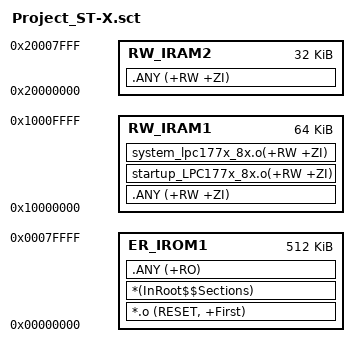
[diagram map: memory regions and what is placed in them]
; *************************************************************
; *** Scatter-Loading Description File generated by uVision ***
; *************************************************************

LR_IROM1 0x00000000 0x00080000  {    ; load region size_region
  ER_IROM1 0x00000000 0x00080000  {  ; load address = execution address
   *.o (RESET, +First)
   *(InRoot$$Sections)
   .ANY (+RO)
  }
  ;RW_RAM1 0xA0000000 UNINIT 0x02000000  {  ; RW data
	;heapstack.o(GlobalVal)
   ;.ANY (+RW +ZI)
   ;startup_LPC177x_8x.o(HEAP)
  ;}
  RW_IRAM1 0x10000000 0x00010000  {
   .ANY (+RW +ZI)
   startup_LPC177x_8x.o(+RW +ZI)
   system_lpc177x_8x.o(+RW +ZI)
  }
  ;RW_IRAM2 0x20000000 PI 0x00008000  {;PI Position Indepedent 
  RW_IRAM2 0x20000000 0x00008000  {
   .ANY (+RW +ZI)
  }
}

